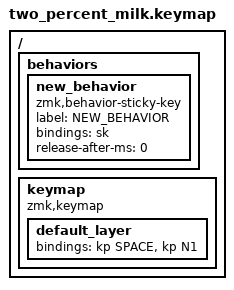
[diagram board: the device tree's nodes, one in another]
/*
 * Copyright (c) 2022 The ZMK Contributors
 *
 * SPDX-License-Identifier: MIT
 */

#include <behaviors.dtsi>
#include <dt-bindings/zmk/keys.h>

/ {
    behaviors {
        new_behavior: new_behavior {
            compatible = "zmk,behavior-sticky-key";
            label = "NEW_BEHAVIOR";
            bindings = <&sk>;
            #binding-cells = <1>;
            release-after-ms = <0>;
        };
    };

    keymap {
        compatible = "zmk,keymap";

        default_layer {
            bindings = <
&kp SPACE  &kp N1
            >;
        };
    };
};
